# STM32F429 register map
File version: 1.2
CPU: CM4 r1p0, little endian, no MPU, no FPU, 3 interrupt priority bits
Registers are 32-bit, read-write, reset 0x0 unless marked. A register's access mark holds for its fields unless they carry their own. Offsets are from the block's base; [hi:lo] are bit positions.

## I2C3 — Inter-integrated circuit
Base 0x40005C00
Same registers: I2C1 0x40005400, I2C2 0x40005800
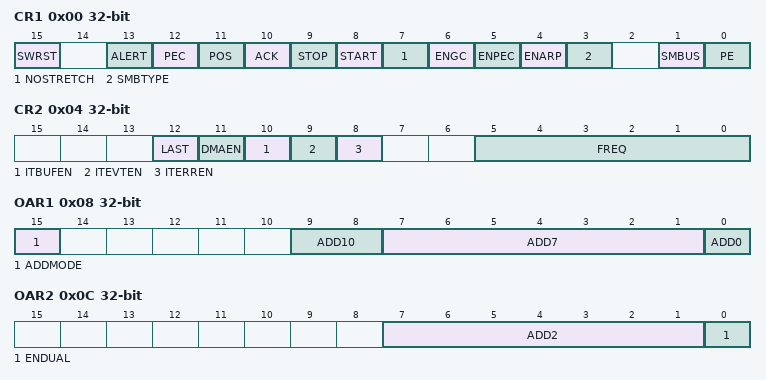
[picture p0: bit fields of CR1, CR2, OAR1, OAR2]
0x00 CR1 — Control register 1
  [15] SWRST — Software reset
  [13] ALERT — SMBus alert
  [12] PEC — Packet error checking
  [11] POS — Acknowledge/PEC Position (for data reception)
  [10] ACK — Acknowledge enable
  [9] STOP — Stop generation
  [8] START — Start generation
  [7] NOSTRETCH — Clock stretching disable (Slave mode)
  [6] ENGC — General call enable
  [5] ENPEC — PEC enable
  [4] ENARP — ARP enable
  [3] SMBTYPE — SMBus type
  [1] SMBUS — SMBus mode
  [0] PE — Peripheral enable
0x04 CR2 — Control register 2
  [12] LAST — DMA last transfer
  [11] DMAEN — DMA requests enable
  [10] ITBUFEN — Buffer interrupt enable
  [9] ITEVTEN — Event interrupt enable
  [8] ITERREN — Error interrupt enable
  [5:0] FREQ — Peripheral clock frequency
0x08 OAR1 — Own address register 1
  [15] ADDMODE — Addressing mode (slave mode)
  [9:8] ADD10 — Interface address
  [7:1] ADD7 — Interface address
  [0] ADD0 — Interface address
0x0C OAR2 — Own address register 2
  [7:1] ADD2 — Interface address
  [0] ENDUAL — Dual addressing mode enable
0x10 DR — Data register
  [7:0] DR — 8-bit data register
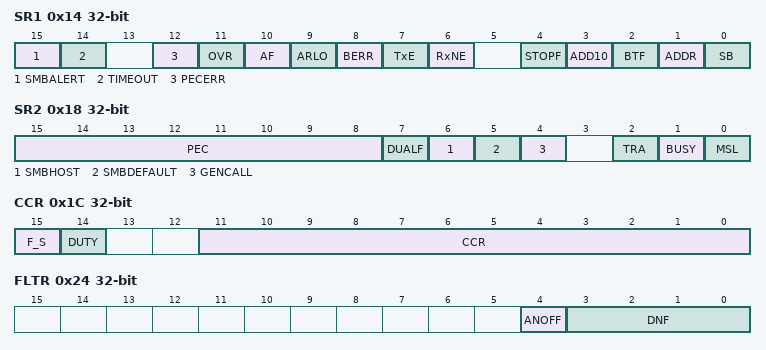
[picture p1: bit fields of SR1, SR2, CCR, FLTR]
0x14 SR1 access per field — Status register 1
  [15] SMBALERT rw — SMBus alert
  [14] TIMEOUT rw — Timeout or Tlow error
  [12] PECERR rw — PEC Error in reception
  [11] OVR rw — Overrun/Underrun
  [10] AF rw — Acknowledge failure
  [9] ARLO rw — Arbitration lost (master mode)
  [8] BERR rw — Bus error
  [7] TxE ro — Data register empty (transmitters)
  [6] RxNE ro — Data register not empty (receivers)
  [4] STOPF ro — Stop detection (slave mode)
  [3] ADD10 ro — 10-bit header sent (Master mode)
  [2] BTF ro — Byte transfer finished
  [1] ADDR ro — Address sent (master mode)/matched (slave mode)
  [0] SB ro — Start bit (Master mode)
0x18 SR2 ro — Status register 2
  [15:8] PEC — acket error checking register
  [7] DUALF — Dual flag (Slave mode)
  [6] SMBHOST — SMBus host header (Slave mode)
  [5] SMBDEFAULT — SMBus device default address (Slave mode)
  [4] GENCALL — General call address (Slave mode)
  [2] TRA — Transmitter/receiver
  [1] BUSY — Bus busy
  [0] MSL — Master/slave
0x1C CCR — Clock control register
  [15] F_S — I2C master mode selection
  [14] DUTY — Fast mode duty cycle
  [11:0] CCR — Clock control register in Fast/Standard mode (Master mode)
0x20 TRISE reset 0x2
  [5:0] TRISE — Maximum rise time in Fast/Standard mode (Master mode)
0x24 FLTR — I2C FLTR register
  [4] ANOFF — Analog noise filter OFF
  [3:0] DNF — Digital noise filter

## FPU — Floting point unit
Base 0xE000EF34
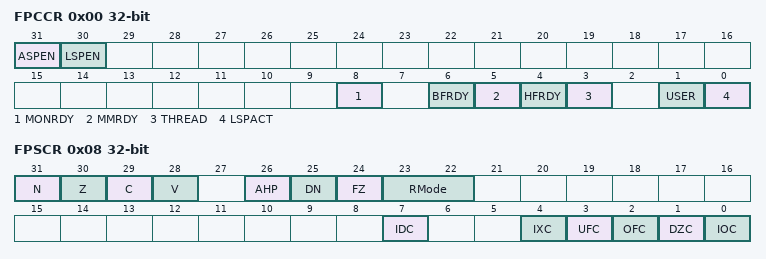
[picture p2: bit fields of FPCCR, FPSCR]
0x00 FPCCR — Floating-point context control register
  [31] ASPEN, [30] LSPEN, [8] MONRDY, [6] BFRDY, [5] MMRDY, [4] HFRDY, [3] THREAD, [1] USER, [0] LSPACT
0x04 FPCAR — Floating-point context address register
  [31:3] ADDRESS — Location of unpopulated floating-point
0x08 FPSCR — Floating-point status control register
  [31] N — Negative condition code flag
  [30] Z — Zero condition code flag
  [29] C — Carry condition code flag
  [28] V — Overflow condition code flag
  [26] AHP — Alternative half-precision control bit
  [25] DN — Default NaN mode control bit
  [24] FZ — Flush-to-zero mode control bit:
  [23:22] RMode — Rounding Mode control field
  [7] IDC — Input denormal cumulative exception bit.
  [4] IXC — Inexact cumulative exception bit
  [3] UFC — Underflow cumulative exception bit
  [2] OFC — Overflow cumulative exception bit
  [1] DZC — Division by zero cumulative exception bit.
  [0] IOC — Invalid operation cumulative exception bit

## MPU — Memory protection unit
Base 0xE000ED90
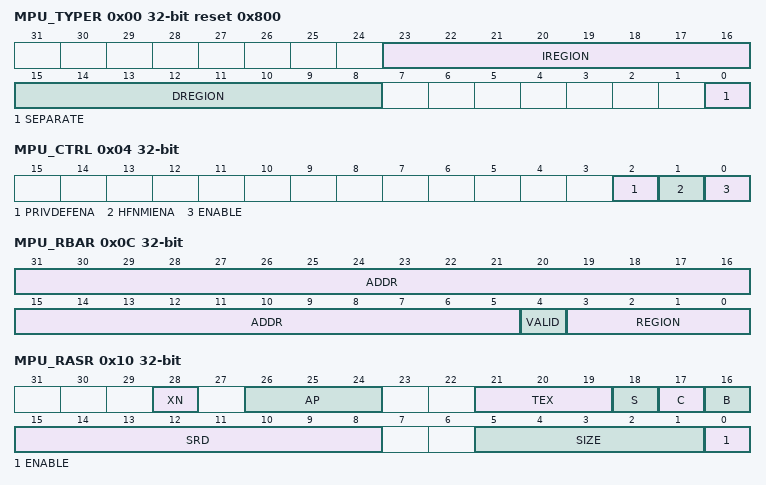
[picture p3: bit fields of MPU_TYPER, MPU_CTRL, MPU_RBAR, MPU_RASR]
0x00 MPU_TYPER ro reset 0x800 — MPU type register
  [23:16] IREGION — Number of MPU instruction regions
  [15:8] DREGION — Number of MPU data regions
  [0] SEPARATE — Separate flag
0x04 MPU_CTRL ro — MPU control register
  [2] PRIVDEFENA — Enable priviliged software access to default memory map
  [1] HFNMIENA — Enables the operation of MPU during hard fault
  [0] ENABLE — Enables the MPU
0x08 MPU_RNR — MPU region number register
  [7:0] REGION — MPU region
0x0C MPU_RBAR — MPU region base address register
  [31:5] ADDR — Region base address field
  [4] VALID — MPU region number valid
  [3:0] REGION — MPU region field
0x10 MPU_RASR — MPU region attribute and size register
  [28] XN — Instruction access disable bit
  [26:24] AP — Access permission
  [21:19] TEX — memory attribute
  [18] S — Shareable memory attribute
  [17] C — memory attribute
  [16] B — memory attribute
  [15:8] SRD — Subregion disable bits
  [5:1] SIZE — Size of the MPU protection region
  [0] ENABLE — Region enable bit.

## STK — SysTick timer
Base 0xE000E010
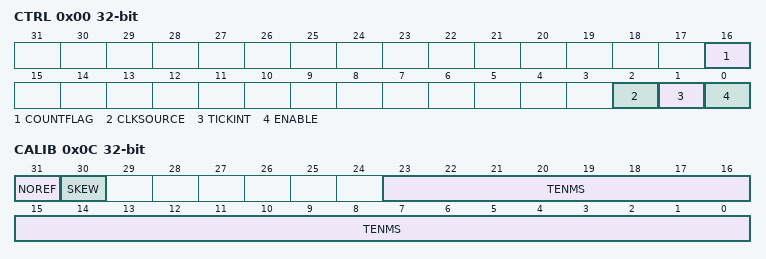
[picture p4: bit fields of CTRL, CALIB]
0x00 CTRL — SysTick control and status register
  [16] COUNTFLAG
  [2] CLKSOURCE — Clock source selection
  [1] TICKINT — SysTick exception request enable
  [0] ENABLE — Counter enable
0x04 LOAD — SysTick reload value register
  [23:0] RELOAD — RELOAD value
0x08 VAL — SysTick current value register
  [23:0] CURRENT — Current counter value
0x0C CALIB — SysTick calibration value register
  [31] NOREF — NOREF flag. Reads as zero
  [30] SKEW — SKEW flag: Indicates whether the TENMS value is exact
  [23:0] TENMS — Calibration value

## NVIC_STIR — Nested vectored interrupt controller
Base 0xE000EF00
0x00 STIR — Software trigger interrupt register
  [8:0] INTID — Software generated interrupt ID

## FPU_CPACR — Floating point unit CPACR
Base 0xE000ED88
0x00 CPACR — Coprocessor access control register
  [23:20] CP

## SCB_ACTRL — System control block ACTLR
Base 0xE000E008
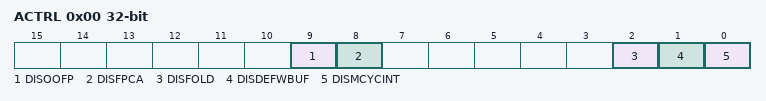
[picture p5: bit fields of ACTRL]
0x00 ACTRL — Auxiliary control register
  [9] DISOOFP, [8] DISFPCA, [2] DISFOLD, [1] DISDEFWBUF, [0] DISMCYCINT
